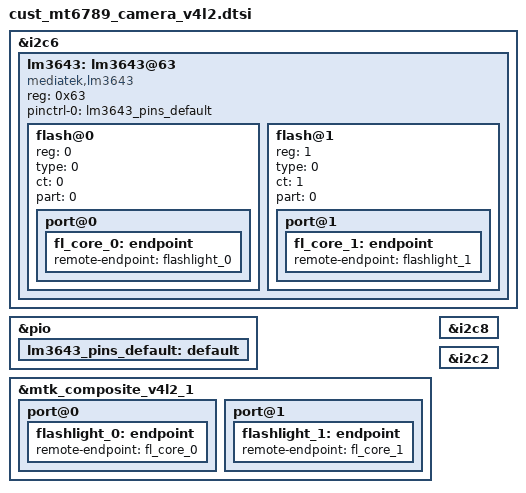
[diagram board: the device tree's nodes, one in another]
// SPDX-License-Identifier: GPL-2.0
/* Copyright (c) 2020 MediaTek Inc. */

&i2c6 {
	lm3643:lm3643@63 {
		compatible = "mediatek,lm3643";
		reg = <0x63>;
		#cooling-cells = <2>;
		pinctrl-names = "default";
		pinctrl-0 = <&lm3643_pins_default>;
		status = "okay";
		flash@0{
			reg = <0>;
			type = <0>;
			ct = <0>;
			part = <0>;
			port@0 {
				fl_core_0: endpoint {
					remote-endpoint = <&flashlight_0>;
				};
			};
		};
		flash@1{
			reg = <1>;
			type = <0>;
			ct = <1>;
			part = <0>;
			port@1 {
				fl_core_1: endpoint {
					remote-endpoint = <&flashlight_1>;
				};
			};
		};
	};
};

&pio {
	lm3643_pins_default: default {
	};
};

&mtk_composite_v4l2_1 {
	port@0 {
		flashlight_0: endpoint {
			remote-endpoint = <&fl_core_0>;
		};
	};
	port@1 {
		flashlight_1: endpoint {
			remote-endpoint = <&fl_core_1>;
		};
	};
};

/* CAMERA AF */
&i2c8 {
/*	camera_main_af_mtk:camera_main_af@72 {
		compatible = "mediatek,camera_main_af";
		reg = <0x72>;
		status = "okay";
	};
*/
};

&i2c2 {
/*	camera_main_two_af_mtk:camera_main_two_af@0d {
		compatible = "mediatek,camera_main_two_af";
		reg = <0x0d>;
		status = "okay";
	};

	camera_main_three_af_mtk:camera_main_three_af@0c {
		compatible = "mediatek,camera_main_three_af";
		reg = <0x0c>;
		status = "okay";
	};
*/
};

/*&camera_af_hw_node {
	camaf_m1_pmic-supply = <&mt6358_vibr_reg>;
	camaf_m2_pmic-supply = <&rt5133_gpio1>;
	camaf_m3_pmic-supply = <&rt5133_gpio1>;
	status = "okay";
};*/
/* CAMERA AF end */
